AUTOSAR XML (schema 4-2-2)
package /AUTOLIV/SoftwareComponents/BswMIf
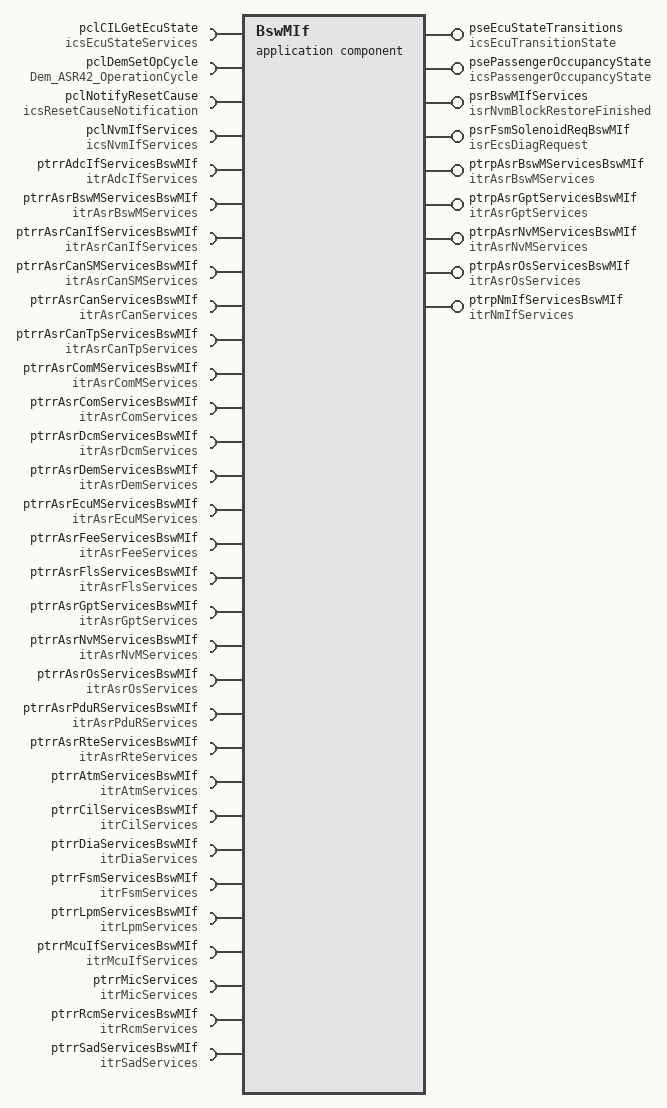
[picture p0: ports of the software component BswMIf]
  application sw component type BswMIf: category=BSW_System_Services
    4 x require port:
      pclCILGetEcuState: client-com-spec=updateCurrentEcuState, required-interface=icsEcuStateServices  # # Architecture Element ID ARCH_SW_BswMIf_pclCILGetEcuState_BswM_Cyclic_10msTimer # Description - The interface shall be used to update the ECU state in CIL module. # Data Flow ## Inputs: - {Current ECU State} # Linked Runnable - BswM_Cyclic_10msTimer #Traceability ---------------------------------------------------------------------------------------------------------------------- # Architecture Element ID ARCH_SW_BswMIf_pclCILGetEcuState_BswM_OnStartupTwoB # Description - The interface shall be used to update the ECU state in CIL module. # Data Flow ## Inputs: - {Current ECU State} # Linked Runnable - BswM_OnStartupTwoB #Traceability ---------------------------------------------------------------------------------------------------------------------- # Architecture Element ID ARCH_SW_BswMIf_pclCILGetEcuState_BswM_OnRunFromWakeup # Description - The interface shall be used to update the ECU state in CIL module. # Data Flow ## Inputs: - {Current ECU State} # Linked Runnable - BswM_OnRunFromWakeup #Traceability ---------------------------------------------------------------------------------------------------------------------- # Architecture Element ID ARCH_SW_BswMIf_pclCILGetEcuState_BswM_OnPostRunFromRun # Description - The interface shall be used to update the ECU state in CIL module. # Data Flow ## Inputs: - {Current ECU State} # Linked Runnable - BswM_OnPostRunFromRun #Traceability ---------------------------------------------------------------------------------------------------------------------- # Architecture Element ID ARCH_SW_BswMIf_pclCILGetEcuState_BswM_OnRunFromPostRunBusAvailable # Description - The interface shall be used to update the ECU state in CIL module. # Data Flow ## Inputs: - {Current ECU State} # Linked Runnable - BswM_OnRunFromPostRunBusAvailable #Traceability ---------------------------------------------------------------------------------------------------------------------- # Architecture Element ID ARCH_SW_BswMIf_pclCILGetEcuState_BswM_OnRunFromPostRunPassengerDetected # Description - The interface shall be used to update the ECU state in CIL module. # Data Flow ## Inputs: - {Current ECU State} # Linked Runnable - BswM_OnRunFromPostRunPassengerDetected #Traceability ---------------------------------------------------------------------------------------------------------------------- # Architecture Element ID ARCH_SW_BswMIf_pclCILGetEcuState_BswM_OnRunFromLowPwrPassengerDetected # Description - The interface shall be used to update the ECU state in CIL module. # Data Flow ## Inputs: - {Current ECU State} # Linked Runnable - BswM_OnRunFromLowPwrPassengerDetected #Traceability ---------------------------------------------------------------------------------------------------------------------- # Architecture Element ID ARCH_SW_BswMIf_pclCILGetEcuState_BswM_OnRunFromLowPwrBusAvailable # Description - The interface shall be used to update the ECU state in CIL module. # Data Flow ## Inputs: - {Current ECU State} # Linked Runnable - BswM_OnRunFromLowPwrBusAvailable #Traceability ----------------------------------------------------------------------------------------------------------------------
      pclDemSetOpCycle: client-com-spec=SetOperationCycleState, required-interface=Dem_ASR42_OperationCycle  # # Architecture Element ID ARCH_SW_BswMIf_pclDemSetOpCycle_BswM_OnStartComEffective # Description - The interface shall be used to set operation cycle of Dem module. # Data Flow ## Inputs: - {Cycle state} # Linked Runnable - BswM_OnStartComEffective #Traceability
      pclNotifyResetCause: client-com-spec=NotifyResetCause, required-interface=icsResetCauseNotification  # # Architecture Element ID ARCH_SW_BswMIf_pclNotifyResetCause_BswM_HWResetNotification # Description - The interface shall be used to set notify the reset casuse in RCM module. # Data Flow ## Inputs: - {Reset Cause Notification Type} - {Reset Cause Status} # Linked Runnable - BswM_HWResetNotification #Traceability --------------------------------------------------------------------------------------------------------------------- # Architecture Element ID ARCH_SW_BswMIf_pclNotifyResetCause_BswM_BswM_SWResetNotification # Description - The interface shall be used to set notify the reset casuse in RCM module. # Data Flow ## Inputs: - {Reset Cause Notification Type} - {Reset Cause Status} # Linked Runnable - BswM_SWResetNotification #Traceability --------------------------------------------------------------------------------------------------------------------- # Architecture Element ID ARCH_SW_BswMIf_pclNotifyResetCause_BswM_JumpToFBLNotification # Description - The interface shall be used to set notify the reset casuse in RCM module. # Data Flow ## Inputs: - {Reset Cause Notification Type} - {Reset Cause Status} # Linked Runnable - BswM_JumpToFBLNotification #Traceability
      pclNvmIfServices: required-interface=icsNvmIfServices  # # Architecture Element ID ARCH_SW_BswMIf_pclNvmIfServices_GetNvmBlockStatus # Description - The interface shall be used to get the current status of a NvM Block # Data Flow ## Inputs: - {Block Id} ## Outputs: - {Block Status} # Linked Runnable - BswMIf_runMainFunction #Traceability ------------------------------------------------------------------------------------------------------------------------------------------------ # Architecture Element ID ARCH_SW_BswMIf_pclNvmIfServices_RestoreRAMBlockDefaults # Description - The interface shall be used to restore to default a RAM Block. # Data Flow ## Inputs: - {Block Id} ## Outputs: - None # Linked Runnable - BswMIf_runMainFunction #Traceability ------------------------------------------------------------------------------------------------------------------------------------------------ # Architecture Element ID ARCH_SW_BswMIf_pclNvmIfServices_SetRamBlockStatus # Description - The interface shall be used to set to set the status of a RAM Block. # Data Flow ## Inputs: - {Block Id} - {Block Status} ## Outputs: - None # Linked Runnable - BswMIf_runMainFunction #Traceability ------------------------------------------------------------------------------------------------------------------------------------------------
        required-com-specs:
          GetNvmBlockLength
          GetNvmBlockStatus
          ReadBlockByAddress
          RestorePRAMBlockDefaults
          SetRamBlockStatus
          WriteBlockByAddress
          WriteNvmBlock
    9 x provide port:
      pseEcuStateTransitions: server-com-spec{operation=BswM_SetEcuStateTransitionStatus, queue-length=1}, provided-interface=icsEcuTransitionState  # # Architecture Element ID ARCH_SW_BswMIf_pseECUStateTransitions # Description - The BswM_SetEcuStateTransitionStatus shall be called in order to set the current status of RunToLowPowerTransition. - This status is necessary because sometimes the BswM Rule is validated before RX Acknowledge and POST RUN state is reached. # Data Flow ## Inputs: - {State of transition} - Can be one of the following values: FALSE, TRUE ## Outputs: - None # Linked Runnable - BswM_SetEcuStateTransitionStatus # Traceability DOM_eCS_TF_P_317
      psePassengerOccupancyState: server-com-spec{operation=BswM_UpdatePassangerOccupancyStatus, queue-length=1}, provided-interface=icsPassengerOccupancyState  # # Architecture Element ID ARCH_SW_BswMIf_psePassengerOccupancyState # Description - The BswM_UpdatePassangerOccupancyStatus shall be called in order to set the status of PassangerOccupancy state. # Data Flow ## Inputs: - {State of passenger occupancy} - PASSENGER_DETECTED ## Outputs: - None # Linked Runnable - BswM_UpdatePassangerOccupancyStatus # Traceability DOM_eCS_TF_P_204, DOM_eCS_TF_P_362, DOM_eCS_TF_P_363
      psrBswMIfServices: nonqueued-sender-com-spec{data-element=u8BlockRestoreStatus, uses-end-to-end-protection=0, init-value=B_FALSE:85}, provided-interface=isrNvmBlockRestoreFinished  # # Architecture Element ID ARCH_SW_BswMIf_psrBswMIfServices # Description - The interface shall be used to write the NvM block restore status from the BswMIf module # Data Flow ## Inputs ## Outputs - {Block Restore Status} - Can be one of the following values: FALSE, TRUE #Linked Runnable - BswMIf_runMainFunction # Traceability
      psrFsmSolenoidReqBswMIf: provided-interface=isrEcsDiagRequest  # # Architecture Element ID ARCH_SW_BswMIf_psrFsmSolenoidReqBswMIf_BswM_OnRunFromSafeState # Description - The runnable shall write the interface in order to trigger an unlock/lock for a certain solenoid # Data Flow ## Inputs: - {On demand self-test} ## Outputs - {Solenoid Command} - Can be UNLOCK/LOCK/NO_REQUEST - {Solenoid Command Complement} - Can be ~UNLOCK/~LOCK/~NO_REQUEST # Linked Runnable - BswM_OnRunFromSafeState # Traceability ----------------------------------------------------------------------------------------------------------------------------- # Architecture Element ID ARCH_SW_BswMIf_psrFsmSolenoidReqBswMIf_BswM_OnSafeStateFromPostRun # Description - The runnable shall write the interface in order to trigger an unlock/lock for a certain solenoid # Data Flow ## Inputs: - {On demand self-test} ## Outputs - {Solenoid Command} - Can be UNLOCK/LOCK/NO_REQUEST - {Solenoid Command Complement} - Can be ~UNLOCK/~LOCK/~NO_REQUEST # Linked Runnable - BswM_OnSafeStateFromPostRun # Traceability DOM_eCS_TF_P_351
        provided-com-specs:
          data-element=au8DiagReq, uses-end-to-end-protection=0, init-value=6 x KU8_NO_DIAG_REQUEST
          data-element=au8DiagReqComplement, uses-end-to-end-protection=0, init-value=6 x KU8_NO_DIAG_REQUEST
      ptrpAsrBswMServicesBswMIf: provided-interface=itrAsrBswMServices  # # Architecture Element ID ARCH_SW_BswMIf_ptrpAsrBswMServicesBswMIf_BswM_OnRunFromSafeState # Description - The BswM_OnRunFromSafeState runnable shall be called by the Autosar BswM in case of: - Transition from WAKEUP to RUN - Transition from LOW POWER to RUN (can wakeup detected) - Transiton from LOW POWER to RUN (passenger detected) # Data Flow #Linked Runnable - BswM_OnRunFromSafeState # Traceability -------------------------------------------------------------------------------------------------------------------------------- # Architecture Element ID ARCH_SW_BswMIf_ptrpAsrBswMServicesBswMIf_BswM_OnSafeStateFromPostRun # Description - The BswM_OnSafeStateFromPostRun runnable shall be called by the Autosar BswM in case of: - Transition from POST RUN to LOW POWER # Data Flow #Linked Runnable - BswM_OnSafeStateFromPostRun # Traceability -------------------------------------------------------------------------------------------------------------------------------- # Architecture Element ID ARCH_SW_BswMIf_ptrpAsrBswMServicesBswMIf_BswM_OnWakeupExpired # Description - The BswM_OnWakeupExpired runnable shall be called by the Autosar BswM in case of: - wakeup validation expired and wakeup status expired after 5000ms # Data Flow #Linked Runnable - BswM_OnWakeupExpired # Traceability DOM_eCS_TF_P_337, DOM_eCS_TF_P_371 -------------------------------------------------------------------------------------------------------------------------------- # Architecture Element ID ARCH_SW_BswMIf_ptrpAsrBswMServicesBswMIf_BswM_HWResetNotification # Description - The BswM_HWResetNotification runnable shall be called by the Autosar BswM in case of: - HW Reset Request # Data Flow #Linked Runnable - BswM_HWResetNotification # Traceability -------------------------------------------------------------------------------------------------------------------------------- # Architecture Element ID ARCH_SW_BswMIf_ptrpAsrBswMServicesBswMIf_BswM_JumpToFBLNotification # Description - The BswM_JumpToFBLNotification runnable shall be called by the Autosar BswM in case of: - Jump to Bootloader Reset Request # Data Flow #Linked Runnable - BswM_JumpToFBLNotification # Traceability DOM_eCS_TF_P_170 -------------------------------------------------------------------------------------------------------------------------------- # Architecture Element ID ARCH_SW_BswMIf_ptrpAsrBswMServicesBswMIf_BswM_SWResetNotification # Description - The BswM_SWResetNotification runnable shall be called by the Autosar BswM in case of: - SW Reset Request # Data Flow #Linked Runnable - BswM_SWResetNotification # Traceability DOM_eCS_TF_P_169 -------------------------------------------------------------------------------------------------------------------------------- # Architecture Element ID ARCH_SW_BswMIf_ptrpAsrBswMServicesBswMIf_BswM_On_Prep_Shutdown # Description - The BswM_On_Prep_Shutdown runnable shall be called by the Autosar BswM in case of: - Post Run timer exceed his maximum value AND buckle and SBS sensors are not available - Low Power timer exceed his maximum value AND no valid passenger occupancy or bus activity is detected # Data Flow #Linked Runnable - BswM_On_Prep_Shutdown # Traceability DOM_eCS_TF_P_284, DOM_eCS_TF_P_285, DOM_eCS_TF_P_216, DOM_eCS_TF_P_373, DOM_eCS_TF_P_374 -------------------------------------------------------------------------------------------------------------------------------- # Architecture Element ID ARCH_SW_BswMIf_ptrpAsrBswMServicesBswMIf_BswM_OnDisableTxPdu # Description - The BswM_OnDisableTxPdu runnable shall be called by the Autosar BswM in case of: - Current state of ECU is RUN AND Bus communication timeout is received # Data Flow #Linked Runnable - BswM_OnDisableTxPdu # Traceability DOM_eCS_TF_P_195, DOM_eCS_TF_P_222 -------------------------------------------------------------------------------------------------------------------------------- # Architecture Element ID ARCH_SW_BswMIf_ptrpAsrBswMServicesBswMIf_BswM_OnEnableTxPdu # Description - The BswM_OnEnableTxPdu runnable shall be called by the Autosar BswM in case of: - Bus communication is available {reception aknowledge is received} # Data Flow #Linked Runnable - BswM_OnEnableTxPdu # Traceability DOM_eCS_TF_P_341, DOM_eCS_TF_P_342, DOM_eCS_TF_P_364, DOM_eCS_TF_P_345, DOM_eCS_TF_P_346, DOM_eCS_TF_P_360, DOM_eCS_TF_P_361, DOM_eCS_TF_P_365, DOM_eCS_TF_P_355, DOM_eCS_TF_P_356, DOM_eCS_TF_P_347 -------------------------------------------------------------------------------------------------------------------------------- # Architecture Element ID ARCH_SW_BswMIf_ptrpAsrBswMServicesBswMIf_BswM_OnGoOffOneA # Description - The BswM_OnGoOffOneA runnable shall be called by the Autosar BswM in case of: - First part of the shutdown procedure {BswM_On_Prep_Shutdown} is made # Data Flow #Linked Runnable - BswM_OnGoOffOneA # Traceability DOM_eCS_TF_P_272 -------------------------------------------------------------------------------------------------------------------------------- # Architecture Element ID ARCH_SW_BswMIf_ptrpAsrBswMServicesBswMIf_BswM_OnLowPwrFromPostRun # Description - The BswM_OnLowPwrFromPostRun runnable shall be called by the Autosar BswM in case of: - Low Power state is requested {current state of ECU is POST RUN State} # Data Flow #Linked Runnable - BswM_OnLowPwrFromPostRun # Traceability DOM_eCS_TF_P_200 -------------------------------------------------------------------------------------------------------------------------------- # Architecture Element ID ARCH_SW_BswMIf_ptrpAsrBswMServicesBswMIf_BswM_OnPostRunFromRun # Description - The BswM_OnPostRunFromRun runnable shall be called by the Autosar BswM in case of: - The current state of ECU is RUN AND Bus communication timeout is received # Data Flow #Linked Runnable - BswM_OnPostRunFromRun # Traceability DOM_eCS_TF_P_168, DOM_eCS_TF_P_190, DOM_eCS_TF_P_263, DOM_eCS_TF_P_350 -------------------------------------------------------------------------------------------------------------------------------- # Architecture Element ID ARCH_SW_BswMIf_ptrpAsrBswMServicesBswMIf_BswM_OnRunFromLowPwrBusAvailable # Description - The BswM_OnRunFromLowPwrBusAvailable runnable shall be called by the Autosar BswM in case of: - The current state of ECU is LOW POWER AND a Passive wakeup is detected {CAN Bus activity} # Data Flow #Linked Runnable - BswM_OnRunFromLowPwrBusAvailable # Traceability DOM_eCS_TF_P_214 -------------------------------------------------------------------------------------------------------------------------------- # Architecture Element ID ARCH_SW_BswMIf_ptrpAsrBswMServicesBswMIf_BswM_OnRunFromLowPwrPassengerDetected # Description - The BswM_OnRunFromLowPwrPassengerDetected runnable shall be called by the Autosar BswM in case of: - The current state of ECU is LOW POWER AND an Active wakeup is detected {passenger occupancy detected} # Data Flow #Linked Runnable - BswM_OnRunFromLowPwrPassengerDetected # Traceability DOM_eCS_TF_P_317, DOM_eCS_TF_P_323 -------------------------------------------------------------------------------------------------------------------------------- # Architecture Element ID ARCH_SW_BswMIf_ptrpAsrBswMServicesBswMIf_BswM_OnRunFromPostRunBusAvailable # Description - The BswM_OnRunFromPostRunBusAvailable runnable shall be called by the Autosar BswM in case of: - The current state of ECU is POST RUN AND Bus communication is available {reception aknowledge is received} # Data Flow #Linked Runnable - BswM_OnRunFromPostRunBusAvailable # Traceability DOM_eCS_TF_P_193, DOM_eCS_TF_P_202 -------------------------------------------------------------------------------------------------------------------------------- # Architecture Element ID ARCH_SW_BswMIf_ptrpAsrBswMServicesBswMIf_BswM_OnRunFromPostRunPassengerDetected # Description - The BswM_OnRunFromPostRunPassengerDetected runnable shall be called by the Autosar BswM in case of: - The current state of ECU is POST RUN AND Valid Passenger occupancy is detected # Data Flow #Linked Runnable - BswM_OnRunFromPostRunPassengerDetected # Traceability DOM_eCS_TF_P_313, DOM_eCS_TF_P_323 -------------------------------------------------------------------------------------------------------------------------------- # Architecture Element ID ARCH_SW_BswMIf_ptrpAsrBswMServicesBswMIf_BswM_OnRunFromWakeup # Description - The BswM_OnRunFromWakeup runnable shall be called by the Autosar BswM in case of: - Wakeup is validated and all modules were initialized {BswM_OnStartComEffective} # Data Flow #Linked Runnable - BswM_OnRunFromWakeup # Traceability DOM_eCS_TF_P_235, DOM_eCS_TF_P_158, DOM_eCS_TF_P_343, DOM_eCS_TF_P_359, DOM_eCS_TF_P_344, DOM_eCS_TF_P_348, DOM_eCS_TF_P_335, DOM_eCS_TF_P_140 -------------------------------------------------------------------------------------------------------------------------------- # Architecture Element ID ARCH_SW_BswMIf_ptrpAsrBswMServicesBswMIf_BswM_OnStartComEffective # Description - The BswM_OnStartComEffective runnable shall be called by the Autosar BswM in case of: - Bus communication is available AND wakeup was validated # Data Flow #Linked Runnable - BswM_OnStartComEffective # Traceability DOM_eCS_TF_P_339, DOM_eCS_TF_P_344, DOM_eCS_TF_P_348 -------------------------------------------------------------------------------------------------------------------------------- # Architecture Element ID ARCH_SW_BswMIf_ptrpAsrBswMServices_BswMIf_BswM_OnStartupTwoA # Description - The BswM_OnStartupTwoA runnable shall be called by the Autosar BswM in case of: - First part of ECU initialization is done {EcuM_StartupOne, EcuM_StartupTwo} # Data Flow #Linked Runnable - BswM_OnStartupTwoA # Traceability DOM_eCS_TF_P_138, DOM_eCS_TF_P_280, DOM_eCS_TF_P_333, DOM_eCS_TF_P_334 -------------------------------------------------------------------------------------------------------------------------------- # Architecture Element ID ARCH_SW_BswMIf_ptrpAsrBswMServicesBswMIf_BswM_OnStartupTwoB # Description - The BswM_OnStartupTwoB runnable shall be called by the Autosar BswM in case of: - ReadAll NvM procedure is made {After second part of ECU initialization - BswM_OnStartupTwoB} # Data Flow #Linked Runnable - BswM_OnStartupTwoB # Traceability DOM_eCS_TF_P_333, DOM_eCS_TF_P_334 -------------------------------------------------------------------------------------------------------------------------------- # Architecture Element ID ARCH_SW_BswMIf_ptrpAsrBswMServicesBswMIf_BswM_OnWakeupValidation # Description - The BswM_OnWakeupValidation runnable shall be called by the Autosar BswM in case of: - Wakeup event is validated # Data Flow #Linked Runnable - BswM_OnWakeupValidation # Traceability DOM_eCS_TF_P_73, DOM_eCS_TF_P_339 -------------------------------------------------------------------------------------------------------------------------------- # Architecture Element ID ARCH_SW_BswMIf_ptrpAsrBswMServicesBswMIf_BswM_ProceedReset # Description - The BswM_ProceedReset runnable shall be called by the Autosar BswM in case of: - SW Reset diagnosis request is made - HW Reset diagnosis request is made - FBL Reset diagnosis request is made # Data Flow #Linked Runnable - BswM_ProceedReset # Traceability DOM_eCS_TF_P_169, DOM_eCS_TF_P_170, DOM_eCS_TF_P_373, DOM_eCS_TF_P_374
      ptrpAsrGptServicesBswMIf: provided-interface=itrAsrGptServices  # # Architecture Element ID ARCH_SW_BswMIf_ptrpAsrGptServicesBswMIf_BswM_Cyclic_10msTimer # Description - The BswM_Cyclic_10msTimer runnable shall be called when the Gpt timer expires via the Gpt_InitChannelPB_TDK_4G runnable # Data Flow # Linked Runnable - BswM_Cyclic_10msTimer # Traceability DOM_eCS_TF_P_277, DOM_eCS_TF_P_278, DOM_eCS_TF_P_279, DOM_eCS_TF_P_192, DOM_eCS_TF_P_257, DOM_eCS_TF_P_285, DOM_eCS_TF_P_284, DOM_eCS_TF_P_202, DOM_eCS_TF_P_313, DOM_eCS_TF_P_263, DOM_eCS_TF_P_200, DOM_eCS_TF_P_235, DOM_eCS_TF_P_323, DOM_eCS_TF_P_349, DOM_eCS_TF_P_159, DOM_eCS_TF_P_350
      ptrpAsrNvMServicesBswMIf: provided-interface=itrAsrNvMServices  # # Architecture Element ID ARCH_SW_BswMIf_ptrpAsrNvMServicesBswMIf_BswM_CB_NfyNvMJobEnd # Description - The BswM_CB_NfyNvMJobEnd runnable shall be called when the NvM Read or Write job is finished. # Data Flow # Linked Runnable - BswM_CB_NfyNvMJobEnd # Traceability DOM_eCS_TF_P_273
      ptrpAsrOsServicesBswMIf: provided-interface=itrAsrOsServices  # # Architecture Element ID ARCH_SW_BswMIf_ptrpAsrOsServicesBswMIf_BswMIf_runMainFunction # Description - The BswMIf_runMainFunction runnable shall be called when the Os task {OsTask_Alv_Autotests} is executed # Data Flow # Linked Runnable - BswMIf_runMainFunction # Traceability DOM_eCS_TF_P_339, DOM_eCS_TF_P_155, DOM_eCS_TF_P_189, DOM_eCS_TF_P_353, DOM_eCS_TF_P_354, DOM_eCS_TF_P_357, DOM_eCS_TF_P_358 -------------------------------------------------------------------------------------------------------------------------------- # Architecture Element ID ARCH_SW_BswMIf_OsTask_Bsw_ReadWrite_AllProcess # Description - The OsTask_Bsw_ReadWrite_AllProcess runnable shall be called when the Os task {OsTask_Bsw_ReadWrite_AllProcess} is executed # Data Flow # Linked Runnable - OsTask_Bsw_ReadWrite_AllProcess # Traceability -------------------------------------------------------------------------------------------------------------------------------- # Architecture Element ID ARCH_SW_BswMIf_OsTask_AppIdle # Description - The OsTask_AppIdle runnable shall be called when the Os task {OsTask_AppIdle} is executed # Data Flow # Linked Runnable - OsTask_AppIdle # Traceability
      ptrpNmIfServicesBswMIf: provided-interface=itrNmIfServices  # # Architecture Element ID ARCH_SW_BswMIf_ptrpNmIfServicesBswMIf_BswM_SetEcuStateTransitionStatus # Description - The BswM_SetEcuStateTransitionStatus runnable shall be called when bus acknowledge is received and NmIf_runMainFunction runnable is executed. # Data Flow # Linked Runnable - BswM_SetEcuStateTransitionStatus # Traceability
    27 x require port:
      ptrrAdcIfServicesBswMIf: required-interface=itrAdcIfServices  # # Architecture Element ID ARCH_SW_BswMIf_ptrrAdcIfServicesBswMIf_AdcIf_runInit_BswM_OnStartupTwoA # Description - The AdcIf_runInit runnable shall be called in the BswM_OnStartupTwoA runnable in order to initialize the AdcIf module and to start the Adc conversions. # Data Flow # Linked Runnable - BswM_OnStartupTwoA #Traceability DOM_eCS_TF_P_311 --------------------------------------------------------------------------------------------------------------------------------------------- # Architecture Element ID ARCH_SW_BswMIf_ptrrAdcIfServicesBswMIf_AdcIf_runDeInit_BswM_OnGoOffOneA # Description - The AdcIf_runDeInit runnable shall be called in the BswM_OnGoOffOneA runnable in order to deinitialize the AdcIf module and to stop the Adc conversions. # Data Flow # Linked Runnable - BswM_OnGoOffOneA #Traceability DOM_eCS_TF_P_272
      ptrrAsrBswMServicesBswMIf: required-interface=itrAsrBswMServices  # # Architecture Element ID ARCH_SW_BswMIf_ptrrBswMServicesBswMIf_BswM_RequestMode_BswM_Cyclic_10msTimer # Description - The BswM_RequestMode runnable shall be called in the BswM_Cyclic_10msTimer runnable in order to: - Set BswM Passenger Occupancy port to notify that pasager occupancy was detected - Set BswM Passenger Occupancy port to notify that pasager occupancy was not detected - Set BswM ECU Shutdown Port to be able to notify that SHUTDOWN state is requested - Set BswM EcuState Port to be able to notify that LOW POWER state is requested - Set BswM EcuState Port to be able to notify that RUN state is requested - Set BswM TX PDU request port to notify that TX Pdu disable is requested # Data Flow # Linked Runnable - BswM_Cyclic_10msTimer #Traceability DOM_eCS_TF_P_192, DOM_eCS_TF_P_257, DOM_eCS_TF_P_285, DOM_eCS_TF_P_284, DOM_eCS_TF_P_313, DOM_eCS_TF_P_263 --------------------------------------------------------------------------------------------------------------------------------------- # Architecture Element ID ARCH_SW_BswMIf_ptrrBswMServicesBswMIf_BswM_RequestMode_BswM_OnStartupTwoA # Description - The BswM_RequestMode runnable shall be called in the BswM_OnStartupTwoA runnable in order to: - Request to start the process to fastened the ReadAll process # Data Flow # Linked Runnable - BswM_OnStartupTwoA #Traceability DOM_eCS_TF_P_295 --------------------------------------------------------------------------------------------------------------------------------------- # Architecture Element ID ARCH_SW_BswMIf_ptrrBswMServicesBswMIf_BswM_RequestMode_BswM_CB_NfyNvMJobEnd # Description - The BswM_RequestMode runnable shall be called in the BswM_CB_NfyNvMJobEnd runnable in order to: - Set BswM Request Port to be able to notify that initialization phase shall continue {init phase - StartupTwoB} - Set BswM Request Port to be able to reset the passenger occupancy status if writeAll procedure is triggered when transition from autonomous run to run is made - Set BswM Request Port to be able to set the ecu state to RUN if writeAll procedure is triggered when transition from autonomous run to run is made - Set BswM Request Port to be able to notify that de-initialization phase shall continue {de-init phase - GoOffOneA} # Data Flow # Linked Runnable - BswM_CB_NfyNvMJobEnd #Traceability --------------------------------------------------------------------------------------------------------------------------------------- # Architecture Element ID ARCH_SW_BswMIf_ptrrBswMServicesBswMIf_BswM_RequestMode_BswM_OnStartupTwoB # Description - The BswM_RequestMode runnable shall be called in the BswM_OnStartupTwoB runnable in order to: - Set BswM Request Port to be able to notify that initialization phase shall continue {wait for wake-up validation} # Data Flow # Linked Runnable - BswM_OnStartupTwoB #Traceability DOM_eCS_TF_P_296 --------------------------------------------------------------------------------------------------------------------------------------- # Architecture Element ID ARCH_SW_BswMIf_ptrrBswMServicesBswMIf_BswM_RequestMode_BswM_OnStartComEffective # Description - The BswM_RequestMode runnable shall be called in the BswM_OnStartComEffective runnable in order to: - Set BswM EcuState Port to be able to notify that Wakeup mode ready state is requested - Set BswM Request Port to be able to notify that wakeup was validated # Data Flow # Linked Runnable - BswM_OnStartComEffective #Traceability --------------------------------------------------------------------------------------------------------------------------------------- # Architecture Element ID ARCH_SW_BswMIf_ptrrBswMServicesBswMIf_BswM_RequestMode_BswM_OnRunFromWakeup # Description - The BswM_RequestMode runnable shall be called in the BswM_OnRunFromWakeup runnable in order to: - Set BswM EcuState Port to be able to notify that RUN state is requested # Data Flow # Linked Runnable - BswM_OnRunFromWakeup #Traceability --------------------------------------------------------------------------------------------------------------------------------------- # Architecture Element ID ARCH_SW_BswMIf_ptrrBswMServicesBswMIf_BswM_RequestMode_BswM_OnPostRunFromRun # Description - The BswM_RequestMode runnable shall be called in the BswM_OnPostRunFromRun runnable in order to: - Request to start the process to fastened the ReadAll process - Set BswM EcuState Port to be able to notify that POST RUN state is requested # Data Flow # Linked Runnable - BswM_OnPostRunFromRun #Traceability DOM_eCS_TF_P_264 --------------------------------------------------------------------------------------------------------------------------------------- # Architecture Element ID ARCH_SW_BswMIf_ptrrBswMServicesBswMIf_BswM_RequestMode_BswM_OnRunFromPostRunBusAvailable # Description - The BswM_RequestMode runnable shall be called in the BswM_OnRunFromPostRunBusAvailable runnable in order to: - Set BswM EcuState Port to be able to notify that RUN state is requested # Data Flow # Linked Runnable - BswM_OnRunFromPostRunBusAvailable #Traceability DOM_eCS_TF_P_193, DOM_eCS_TF_P_202 --------------------------------------------------------------------------------------------------------------------------------------- # Architecture Element ID ARCH_SW_BswMIf_ptrrBswMServicesBswMIf_BswM_RequestMode_BswM_OnRunFromPostRunPassengerDetected # Description - The BswM_RequestMode runnable shall be called in the BswM_OnRunFromPostRunPassengerDetected runnable in order to: - Set BswM EcuState Port to be able to notify that RUN NO COMM state is requested - Set BswM TX PDU request port to notify that wait TX Pdu is requested {used to not trigger other rules} # Data Flow # Linked Runnable - BswM_OnRunFromPostRunPassengerDetected #Traceability --------------------------------------------------------------------------------------------------------------------------------------- # Architecture Element ID ARCH_SW_BswMIf_ptrrBswMServicesBswMIf_BswM_RequestMode_BswM_OnLowPwrFromPostRun # Description - The BswM_RequestMode runnable shall be called in the BswM_OnLowPwrFromPostRun runnable in order to: - Set BswM EcuState Port to be able to notify that LOW POWER state is requested # Data Flow # Linked Runnable - BswM_OnLowPwrFromPostRun #Traceability DOM_eCS_TF_P_200 --------------------------------------------------------------------------------------------------------------------------------------- # Architecture Element ID ARCH_SW_BswMIf_ptrrBswMServicesBswMIf_BswM_RequestMode_BswM_OnRunFromLowPwrPassengerDetected # Description - The BswM_RequestMode runnable shall be called in the BswM_OnRunFromLowPwrPassengerDetected runnable in order to: - Set BswM EcuState Port to be able to notify that RUN state is requested # Data Flow # Linked Runnable - BswM_OnRunFromLowPwrPassengerDetected #Traceability --------------------------------------------------------------------------------------------------------------------------------------- # Architecture Element ID ARCH_SW_BswMIf_ptrrBswMServicesBswMIf_BswM_RequestMode_BswM_OnRunFromLowPwrBusAvailable # Description - The BswM_RequestMode runnable shall be called in the BswM_OnRunFromLowPwrBusAvailable runnable in order to: - Set BswM EcuState Port to be able to notify that RUN state is requested # Data Flow # Linked Runnable - BswM_OnRunFromLowPwrBusAvailable #Traceability DOM_eCS_TF_P_214 --------------------------------------------------------------------------------------------------------------------------------------- # Architecture Element ID ARCH_SW_BswMIf_ptrrBswMServicesBswMIf_BswM_RequestMode_BswM_On_Prep_Shutdown # Description - The BswM_RequestMode runnable shall be called in the BswM_On_Prep_Shutdown runnable in order to: - Request to start the process to fastened the WriteAll process - Set BswM Request Port to be able to notify that de-initialization of modules shall be performed # Data Flow # Linked Runnable - BswM_On_Prep_Shutdown #Traceability DOM_eCS_TF_P_272 --------------------------------------------------------------------------------------------------------------------------------------- # Architecture Element ID ARCH_SW_BswMIf_ptrrBswMServicesBswMIf_BswM_RequestMode_BswM_OnGoOffOneA # Description - The BswM_RequestMode runnable shall be called in the BswM_OnGoOffOneA runnable in order to: - Set BswM Request Port to be able to notify that the second step of de-initialization of modules shall be performed # Data Flow # Linked Runnable - BswM_OnGoOffOneA #Traceability DOM_eCS_TF_P_272 --------------------------------------------------------------------------------------------------------------------------------------- # Architecture Element ID ARCH_SW_BswMIf_ptrrBswMServicesBswMIf_BswM_RequestMode_BswMIf_runMainFunction # Description - The BswM_RequestMode runnable shall be called in the BswMIf_runMainFunction runnable in order to: - Set BswM Request Port to be able to notify that PROCESS MODE state is requested # Data Flow # Linked Runnable - BswMIf_runMainFunction #Traceability
      ptrrAsrCanIfServicesBswMIf: required-interface=itrAsrCanIfServices  # # Architecture Element ID ARCH_SW_BswMIf_ptrrCanIfServicesBswMIf_CanIf_Init_BswM_OnStartupTwoA # Description - The CanIf_Init runnable shall be called in the BswM_OnStartupTwoA runnable in order to initialize the CAN interface. # Data Flow # Linked Runnable - BswM_OnStartupTwoA #Traceability --------------------------------------------------------------------------------------------------------------------------------------- # Architecture Element ID ARCH_SW_BswMIf_ptrrCanIfServicesBswMIf_CanIf_CheckWakeup_BswM_CB_NfyNvMJobEnd # Description - The CanIf_CheckWakeup runnable shall be called in the BswM_CB_NfyNvMJobEnd runnable in order to check for wakeup events. # Data Flow # Linked Runnable - BswM_CB_NfyNvMJobEnd #Traceability DOM_eCS_TF_P_152
      ptrrAsrCanSMServicesBswMIf: required-interface=itrAsrCanSMServices  # # Architecture Element ID ARCH_SW_BswMIf_ptrrCanSMServicesBswMIf_CanSM_Init_BswM_OnStartupTwoA # Description - The CanSM_Init runnable shall be called in the BswM_OnStartupTwoA runnable in order to initialize the CanSM module. # Data Flow # Linked Runnable - BswM_OnStartupTwoA #Traceability
      ptrrAsrCanServicesBswMIf: required-interface=itrAsrCanServices  # # Architecture Element ID ARCH_SW_BswMIf_ptrrCanServicesBswMIf_Can_SetControllerMode_BswM_OnStartupTwoA # Description - The Can_SetControllerMode runnable shall be called in the BswM_OnStartupTwoA runnable in order to put the CAN controller in START State. # Data Flow # Linked Runnable - BswM_OnStartupTwoA #Traceability ------------------------------------------------------------------------------------------------------------------------------------------- # Architecture Element ID ARCH_SW_BswMIf_ptrrCanServicesBswMIf_Can_EnableControllerInterrupts_BswM_OnStartupTwoA # Description - The Can_EnableControllerInterrupts runnable shall be called in the BswM_OnStartupTwoA runnable in order to enable CAN interrupts. # Data Flow # Linked Runnable - BswM_OnStartupTwoA #Traceability
      ptrrAsrCanTpServicesBswMIf: required-interface=itrAsrCanTpServices  # # Architecture Element ID ARCH_SW_BswMIf_ptrrCanTpServicesBswMIf_CanTp_Init_BswM_OnStartupTwoA # Description - The CanTp_Init runnable shall be called in the BswM_OnStartupTwoA runnable in order to initialize the CanTp module. # Data Flow # Linked Runnable - BswM_OnStartupTwoA #Traceability
      ptrrAsrComMServicesBswMIf: required-interface=itrAsrComMServices  # # Architecture Element ID ARCH_SW_BswMIf_ptrrComMServicesBswMIf_ComM_Init_BswM_OnStartupTwoB # Description - The ComM_Init runnable shall be called in the BswM_OnStartupTwoB runnable in order to initialize the ComM module. # Data Flow # Linked Runnable - BswM_OnStartupTwoB #Traceability -------------------------------------------------------------------------------------------------------------------------------------------------------- # Architecture Element ID ARCH_SW_BswMIf_ptrrComMServicesBswMIf_ComM_CommunicationAllowed_BswM_OnWakeupValidation # Description - The ComM_CommunicationAllowed runnable shall be called in the BswM_OnWakeupValidation runnable in order to authorize the start of communication # Data Flow # Linked Runnable - BswM_OnWakeupValidation #Traceability DOM_eCS_TF_P_153, DOM_eCS_TF_P_301 -------------------------------------------------------------------------------------------------------------------------------------------------------- # Architecture Element ID ARCH_SW_BswMIf_ptrrComMServicesBswMIf_ComM_ASR40_RequestComMode_BswM_OnWakeupValidation # Description - The ComM_ASR40_RequestComMode runnable shall be called in the BswM_OnWakeupValidation runnable in order to enable message transmission and reception. # Data Flow # Linked Runnable - BswM_OnWakeupValidation #Traceability DOM_eCS_TF_P_153, DOM_eCS_TF_P_300, DOM_eCS_TF_P_163, DOM_eCS_TF_P_166 -------------------------------------------------------------------------------------------------------------------------------------------------------- # Architecture Element ID ARCH_SW_BswMIf_ptrrComMServicesBswMIf_ComM_ASR40_RequestComMode_BswM_OnPostRunFromRun # Description - The ComM_ASR40_RequestComMode runnable shall be called in the BswM_OnPostRunFromRun runnable in order to set ComM back to full communication to be able to detect a wake-up request after post run state was entered. # Data Flow # Linked Runnable - BswM_OnPostRunFromRun #Traceability DOM_eCS_TF_P_194 -------------------------------------------------------------------------------------------------------------------------------------------------------- # Architecture Element ID ARCH_SW_BswMIf_ptrrComMServicesBswMIf_ComM_DeInit_BswM_OnGoOffOneA # Description - The ComM_DeInit runnable shall be called in the BswM_OnGoOffOneA runnable in order to de-initialize the ComM module. # Data Flow # Linked Runnable - BswM_OnGoOffOneA #Traceability DOM_eCS_TF_P_272, DOM_eCS_TF_P_367
      ptrrAsrComServicesBswMIf: required-interface=itrAsrComServices  # # Architecture Element ID ARCH_SW_BswMIf_ptrrComServicesBswMIf_Com_Init_BswM_OnStartupTwoA # Description - The Com_Init runnable shall be called in the BswM_OnStartupTwoA runnable in order to initialize the Com module. # Data Flow # Linked Runnable - BswM_OnStartupTwoA #Traceability -------------------------------------------------------------------------------------------------------------------------------------------------------- # Architecture Element ID ARCH_SW_BswMIf_ptrrComServicesBswMIf_Com_ClearIpduGroupVector_BswM_OnDisableTxPdu # Description - The Com_ClearIpduGroupVector runnable shall be called in the BswM_OnDisableTxPdu runnable in order to initialize the PDU group vector to 0 # Data Flow # Linked Runnable - BswM_OnDisableTxPdu #Traceability -------------------------------------------------------------------------------------------------------------------------------------------------------- # Architecture Element ID ARCH_SW_BswMIf_ptrrComServicesBswMIf_Com_SetIpduGroup_BswM_OnDisableTxPdu # Description - The Com_SetIpduGroup runnable shall be called in the BswM_OnDisableTxPdu runnable in order to set new states to RX and Tx Com IPDUs: - Enable frame reception - Disable frame transmission # Data Flow # Linked Runnable - BswM_OnDisableTxPdu #Traceability -------------------------------------------------------------------------------------------------------------------------------------------------------- # Architecture Element ID ARCH_SW_BswMIf_ptrrComServicesBswMIf_Com_IpduGroupControl_BswM_OnDisableTxPdu # Description - The Com_IpduGroupControl runnable shall be called in the BswM_OnDisableTxPdu runnable in order to start both COM PDUs (after their states have been updated) # Data Flow # Linked Runnable - BswM_OnDisableTxPdu #Traceability -------------------------------------------------------------------------------------------------------------------------------------------------------- # Architecture Element ID ARCH_SW_BswMIf_ptrrComServicesBswMIf_Com_ClearIpduGroupVector_BswM_OnEnableTxPdu # Description - The Com_ClearIpduGroupVector runnable shall be called in the BswM_OnEnableTxPdu runnable in order to initialize the PDU group vector to 0 # Data Flow # Linked Runnable - BswM_OnEnableTxPdu #Traceability DOM_eCS_TF_P_166 -------------------------------------------------------------------------------------------------------------------------------------------------------- # Architecture Element ID ARCH_SW_BswMIf_ptrrComServicesBswMIf_Com_SetIpduGroup_BswM_OnEnableTxPdu # Description - The Com_SetIpduGroup runnable shall be called in the BswM_OnEnableTxPdu runnable in order to set new states to RX and Tx Com IPDUs: - Enable frame reception - Enable frame transmission # Data Flow # Linked Runnable - BswM_OnEnableTxPdu #Traceability DOM_eCS_TF_P_166 -------------------------------------------------------------------------------------------------------------------------------------------------------- # Architecture Element ID ARCH_SW_BswMIf_ptrrComServicesBswMIf_Com_IpduGroupControl_BswM_OnEnableTxPdu # Description - The Com_IpduGroupControl runnable shall be called in the BswM_OnEnableTxPdu runnable in order to start both COM PDUs (after their states have been updated) # Data Flow # Linked Runnable - BswM_OnEnableTxPdu #Traceability DOM_eCS_TF_P_166
      ptrrAsrDcmServicesBswMIf: required-interface=itrAsrDcmServices  # # Architecture Element ID ARCH_SW_BswMIf_ptrrDcmServicesBswMIf_Dcm_Init_BswM_OnStartComEffective # Description - The Dcm_Init runnable shall be called in the BswM_OnStartComEffective runnable in order to initialize DCM module # Data Flow # Linked Runnable - BswM_OnStartComEffective #Traceability
      ptrrAsrDemServicesBswMIf: required-interface=itrAsrDemServices  # # Architecture Element ID ARCH_SW_BswMIf_ptrrDemServicesBswMIf_Dem_Init_BswM_OnStartupTwoB # Description - The Dem_Init runnable shall be called in the BswM_OnStartupTwoB runnable in order to initialize DEM module # Data Flow # Linked Runnable - BswM_OnStartupTwoB #Traceability -------------------------------------------------------------------------------------------------------------------------------------------------- # Architecture Element ID ARCH_SW_BswMIf_ptrrDemServicesBswMIf_Dem_Shutdown_BswM_On_Prep_Shutdown # Description - The Dem_Shutdown runnable shall be called in the BswM_On_Prep_Shutdown runnable in order to shutdown the DEM module # Data Flow # Linked Runnable - BswM_On_Prep_Shutdown #Traceability DOM_eCS_TF_P_272
      ptrrAsrEcuMServicesBswMIf: required-interface=itrAsrEcuMServices  # # Architecture Element ID ARCH_SW_BswMIf_ptrrEcuMServicesBswMIf_EcuM_ValidateWakeupEvent_BswM_OnStartupTwoB # Description - The EcuM_ValidateWakeupEvent runnable shall be called in the BswM_OnStartupTwoB runnable in order to validate wakeup event # Data Flow # Linked Runnable - BswM_OnStartupTwoB #Traceability DOM_eCS_TF_P_296, DOM_eCS_TF_P_273, DOM_eCS_TF_P_237 --------------------------------------------------------------------------------------------------------------------------------------------- # Architecture Element ID ARCH_SW_BswMIf_ptrrEcuMServicesBswMIf_EcuM_ClearWakeupEvent_BswM_OnStartComEffective # Description - The EcuM_ClearWakeupEvent runnable shall be called in the BswM_OnStartComEffective runnable in order to acknowledge wake validation information # Data Flow # Linked Runnable - BswM_OnStartComEffective #Traceability DOM_eCS_TF_P_303 --------------------------------------------------------------------------------------------------------------------------------------------- # Architecture Element ID ARCH_SW_BswMIf_ptrrEcuMServicesBswMIf_EcuM_ClearWakeupEvent_BswM_On_Prep_Shutdown # Description - The EcuM_ClearWakeupEvent runnable shall be called in the BswM_On_Prep_Shutdown runnable in order to acknowledge wake validation information # Data Flow # Linked Runnable - BswM_On_Prep_Shutdown #Traceability --------------------------------------------------------------------------------------------------------------------------------------------- # Architecture Element ID ARCH_SW_BswMIf_ptrrEcuMServicesBswMIf_EcuM_GoDown_BswM_ProceedReset # Description - The EcuM_GoDown runnable shall be called in the BswM_ProceedReset runnable in order to prepare for a power off/reset # Data Flow # Linked Runnable - BswM_ProceedReset #Traceability DOM_eCS_TF_P_218 --------------------------------------------------------------------------------------------------------------------------------------------- # Architecture Element ID ARCH_SW_BswMIf_ptrrEcuMServicesBswMIf_EcuM_GoDown_BswM_OnWakeupExpired # Description - The EcuM_GoDown runnable shall be called in the BswM_OnWakeupExpired runnable in order to prepare for a power off/reset # Data Flow # Linked Runnable - BswM_OnWakeupExpired #Traceability
      ptrrAsrFeeServicesBswMIf: required-interface=itrAsrFeeServices  # # Architecture Element ID ARCH_SW_BswMIf_ptrrFeeServicesBswMIf_Fee_MainFunction_OsTask_Bsw_ReadWrite_AllProcess # Description - The Fee_MainFunction runnable shall be called in the OsTask_Bsw_ReadWrite_AllProcess runnable in order to read/write or erase fee jobs # Data Flow # Linked Runnable - OsTask_Bsw_ReadWrite_AllProcess #Traceability DOM_eCS_TF_P_295, DOM_eCS_TF_P_273
      ptrrAsrFlsServicesBswMIf: required-interface=itrAsrFlsServices  # # Architecture Element ID ARCH_SW_BswMIf_ptrrFlsServicesBswMIf_Fls_MainFunction_OsTask_Bsw_ReadWrite_AllProcess # Description - The Fls_MainFunction runnable shall be called in the OsTask_Bsw_ReadWrite_AllProcess runnable in order to perform flash read/write/erase or compare fls jobs # Data Flow # Linked Runnable - OsTask_Bsw_ReadWrite_AllProcess #Traceability DOM_eCS_TF_P_295, DOM_eCS_TF_P_273
      ptrrAsrGptServicesBswMIf: required-interface=itrAsrGptServices  # # Architecture Element ID ARCH_SW_BswMIf_ptrrGptServicesBswMIf_Gpt_StopTimer_BswM_Cyclic_10msTimer # Description - The Gpt_StopTimer runnable shall be called in the BswM_Cyclic_10msTimer runnable in order to stop function of timer if: - Current ECU State is POST RUN AND Pasager occupancy is detected - Current ECU State is POST RUN AND Passenger occupancy OR CAN Activity is not detected - Current ECU State is AUTONOMOUS RUN {Passenger detected - valid transition from POST RUN} AND CAN Activity was detected on bus - Current ECU State is AUTONOMOUS RUN {Passenger detected - valid transition from POST RUN} AND CAN Activity was not detected on bus - Current ECU State is AUTONOMOUS RUN {Passenger detected - valid transition from LOW POWER} AND CAN Activity was detected on bus - Current ECU State is AUTONOMOUS RUN {Passenger detected - valid transition from LOW POWER} AND CAN Activity was not detected on bus # Data Flow # Linked Runnable - BswM_Cyclic_10msTimer #Traceability DOM_eCS_TF_P_284, DOM_eCS_TF_P_285, DOM_eCS_TF_P_313, DOM_eCS_TF_P_263 ---------------------------------------------------------------------------------------------------------------------------------------------------------------------------- # Architecture Element ID ARCH_SW_BswMIf_ptrrGptServicesBswMIf_Gpt_StartTimer_BswM_CB_NfyNvMJobEnd # Description - The Gpt_StartTimer runnable shall be called in the BswM_CB_NfyNvMJobEnd runnable in order to start GPT timer if: - WriteAll request was made by a valid transition from RUN in POST RUN # Data Flow # Linked Runnable - BswM_CB_NfyNvMJobEnd #Traceability DOM_eCS_TF_P_264 ---------------------------------------------------------------------------------------------------------------------------------------------------------------------------- # Architecture Element ID ARCH_SW_BswMIf_ptrrGptServicesBswMIf_Gpt_EnableNotification_BswM_OnStartupTwoB # Description - The Gpt_EnableNotification runnable shall be called in the BswM_OnStartupTwoB runnable in order to enable notification function on GPT timer. # Data Flow # Linked Runnable - BswM_OnStartupTwoB #Traceability ---------------------------------------------------------------------------------------------------------------------------------------------------------------------------- # Architecture Element ID ARCH_SW_BswMIf_ptrrGptServicesBswMIf_Gpt_StopTimer_BswM_OnRunFromPostRunBusAvailable # Description - The Gpt_StopTimer runnable shall be called in the BswM_OnRunFromPostRunBusAvailable runnable in order to stop GPT timer on LPIT2 if: - Ecu enters in RUN State {from POST RUN} # Data Flow # Linked Runnable - BswM_OnRunFromPostRunBusAvailable #Traceability DOM_eCS_TF_P_315, DOM_eCS_TF_P_202 ---------------------------------------------------------------------------------------------------------------------------------------------------------------------------- # Architecture Element ID ARCH_SW_BswMIf_ptrrGptServicesBswMIf_Gpt_StartTimer_BswM_OnRunFromPostRunPassengerDetected # Description - The Gpt_StartTimer runnable shall be called in the BswM_OnPostRunFromRun runnable in order to start GPT timer on LPIT2 if: - Ecu enters in RUN State {from POST RUN} # Data Flow # Linked Runnable - BswM_OnRunFromPostRunPassengerDetected #Traceability ---------------------------------------------------------------------------------------------------------------------------------------------------------------------------- # Architecture Element ID ARCH_SW_BswMIf_ptrrGptServicesBswMIf_Gpt_StartTimer_BswM_OnRunFromLowPwrPassengerDetected # Description - The Gpt_StartTimer runnable shall be called in the BswM_OnRunFromLowPwrPassengerDetected runnable in order to start GPT timer on LPIT2 if: - Ecu enters in RUN State {from LOW POWER} # Data Flow # Linked Runnable - BswM_OnRunFromLowPwrPassengerDetected #Traceability
      ptrrAsrNvMServicesBswMIf: required-interface=itrAsrNvMServices  # # Architecture Element ID ARCH_SW_BswMIf_ptrrNvMServicesBswMIf_NvM_Init_BswM_OnStartupTwoA # Description - The NvM_Init runnable shall be called in the BswM_OnStartupTwoA runnable in order to initialize NvM stack. # Data Flow # Linked Runnable - BswM_OnStartupTwoA #Traceability --------------------------------------------------------------------------------------------------------------------------------- # Architecture Element ID ARCH_SW_BswMIf_ptrrNvMServicesBswMIf_NvM_ReadAll_BswM_OnStartupTwoA # Description - The NvM_ReadAll runnable shall be called in the BswM_OnStartupTwoA runnable in order to start Read All process. # Data Flow # Linked Runnable - BswM_OnStartupTwoA #Traceability DOM_eCS_TF_P_295 --------------------------------------------------------------------------------------------------------------------------------- # Architecture Element ID ARCH_SW_BswMIf_ptrrNvMServicesBswMIf_NvM_WriteAll_BswM_OnPostRunFromRun # Description - The NvM_WriteAll runnable shall be called in the BswM_OnPostRunFromRun runnable in order to start Write All process. # Data Flow # Linked Runnable - BswM_OnPostRunFromRun #Traceability DOM_eCS_TF_P_264 --------------------------------------------------------------------------------------------------------------------------------- # Architecture Element ID ARCH_SW_BswMIf_ptrrNvMServicesBswMIf_NvM_WriteAll_BswM_Cyclic_10msTimer # Description - The NvM_WriteAll runnable shall be called in the BswM_Cyclic_10msTimer runnable in order to start Write All process. # Data Flow # Linked Runnable - BswM_OnPostRunFromRun #Traceability DOM_eCS_TF_P_264 --------------------------------------------------------------------------------------------------------------------------------- # Architecture Element ID ARCH_SW_BswMIf_ptrrNvMServicesBswMIf_NvM_WriteAll_BswM_On_Prep_Shutdown # Description - The NvM_WriteAll runnable shall be called in the BswM_On_Prep_Shutdown runnable in order to start Write All process. # Data Flow # Linked Runnable - BswM_On_Prep_Shutdown #Traceability DOM_eCS_TF_P_273 --------------------------------------------------------------------------------------------------------------------------------- # Architecture Element ID ARCH_SW_BswMIf_ptrrNvMServicesBswMIf_NvM_MainFunction_OsTask_Bsw_ReadWrite_AllProcess # Description - The NvM_MainFunction runnable shall be called in the OsTask_Bsw_ReadWrite_AllProcess runnable in order to manage NvM jobs. # Data Flow # Linked Runnable - OsTask_Bsw_ReadWrite_AllProcess #Traceability DOM_eCS_TF_P_295, DOM_eCS_TF_P_273
      ptrrAsrOsServicesBswMIf: required-interface=itrAsrOsServices  # # Architecture Element ID ARCH_SW_BswMIf_ptrrOsServicesBswMIf_StartScheduleTableRel_BswM_On_Prep_Shutdown # Description - The StartScheduleTableRel runnable shall be called in the BswM_On_Prep_Shutdown runnable in order to start the default schedule table after main schedule table (RTE) was stopped. # Data Flow # Linked Runnable - BswM_On_Prep_Shutdown #Traceability --------------------------------------------------------------------------------------------------------------------------------- # Architecture Element ID ARCH_SW_BswMIf_ptrrOsServicesBswMIf_StartScheduleTableRel_BswM_OnPostRunFromRun # Description - The StartScheduleTableRel runnable shall be called in the BswM_OnPostRunFromRun runnable in order to start the main schedule table after WriteAll procedure is finished. # Data Flow # Linked Runnable - BswM_OnPostRunFromRun #Traceability --------------------------------------------------------------------------------------------------------------------------------- # Architecture Element ID ARCH_SW_BswMIf_ptrrOsServicesBswMIf_StopScheduleTable_BswM_OnPostRunFromRun # Description - The StopScheduleTable runnable shall be called in the BswM_OnPostRunFromRun runnable in order to stop the default schedule table used to call the ReadWriteAll Os task. # Data Flow # Linked Runnable - BswM_OnPostRunFromRun #Traceability --------------------------------------------------------------------------------------------------------------------------------- # Architecture Element ID ARCH_SW_BswMIf_ptrrOsServicesBswMIf_StopScheduleTable_BswM_CB_NfyNvMJobEnd # Description - The StopScheduleTable runnable shall be called in the BswM_CB_NfyNvMJobEnd runnable in order to stop the default schedule table used to call the ReadWriteAll Os task. # Data Flow # Linked Runnable - BswM_CB_NfyNvMJobEnd #Traceability --------------------------------------------------------------------------------------------------------------------------------- # Architecture Element ID ARCH_SW_BswMIf_ptrrOsServicesBswMIf_StartScheduleTableRel_BswM_CB_NfyNvMJobEnd # Description - The StartScheduleTableRel runnable shall be called in the BswM_CB_NfyNvMJobEnd runnable in order to start the main schedule table after WriteAll procedure is finished. # Data Flow # Linked Runnable - BswM_CB_NfyNvMJobEnd #Traceability --------------------------------------------------------------------------------------------------------------------------------- # Architecture Element ID ARCH_SW_BswMIf_ptrrOsServicesBswMIf_ActivateTask_BswM_OnPostRunFromRun # Description - The ActivateTask runnable shall be called in the BswM_OnPostRunFromRun runnable in order to activate the task dedicated to the ReadAll process fastening. # Data Flow # Linked Runnable - BswM_OnPostRunFromRun #Traceability --------------------------------------------------------------------------------------------------------------------------------- # Architecture Element ID ARCH_SW_BswMIf_ptrrOsServicesBswMIf_ActivateTask_BswM_OnStartupTwoA # Description - The ActivateTask runnable shall be called in the BswM_OnStartupTwoA runnable in order to activate the task dedicated to the ReadAll process fastening. # Data Flow # Linked Runnable - BswM_OnStartupTwoA #Traceability DOM_eCS_TF_P_295 --------------------------------------------------------------------------------------------------------------------------------- # Architecture Element ID ARCH_SW_BswMIf_ptrrOsServicesBswMIf_SetEvent_BswM_OnStartupTwoA # Description - The SetEvent runnable shall be called in the BswM_OnStartupTwoA runnable in order to set the task dedicated to the ReadAll process fastening. # Data Flow # Linked Runnable - BswM_OnStartupTwoA #Traceability DOM_eCS_TF_P_295 --------------------------------------------------------------------------------------------------------------------------------- # Architecture Element ID ARCH_SW_BswMIf_ptrrOsServicesBswMIf_StopScheduleTable_BswM_OnStartComEffective # Description - The StopScheduleTable runnable shall be called in the BswM_OnStartComEffective runnable in order to stop the default schedule table to be able to start the main schedule table. # Data Flow # Linked Runnable - BswM_OnStartComEffective #Traceability --------------------------------------------------------------------------------------------------------------------------------- # Architecture Element ID ARCH_SW_BswMIf_ptrrOsServicesBswMIf_SetEvent_BswM_OnPostRunFromRun # Description - The SetEvent runnable shall be called in the BswM_OnPostRunFromRun runnable in order to set the task dedicated to the WriteAll process fastening. # Data Flow # Linked Runnable - BswM_OnPostRunFromRun #Traceability DOM_eCS_TF_P_264 --------------------------------------------------------------------------------------------------------------------------------- # Architecture Element ID ARCH_SW_BswMIf_ptrrOsServicesBswMIf_ActivateTask_BswM_On_Prep_Shutdown # Description - The ActivateTask runnable shall be called in the BswM_On_Prep_Shutdown runnable in order to activate the task dedicated to the WriteAll process fastening. # Data Flow # Linked Runnable - BswM_On_Prep_Shutdown #Traceability DOM_eCS_TF_P_273 --------------------------------------------------------------------------------------------------------------------------------- # Architecture Element ID ARCH_SW_BswMIf_ptrrOsServicesBswMIf_SetEvent_BswM_On_Prep_Shutdown # Description - The SetEvent runnable shall be called in the BswM_On_Prep_Shutdown runnable in order to set the task dedicated to the WriteAll process fastening. # Data Flow # Linked Runnable - BswM_On_Prep_Shutdown #Traceability DOM_eCS_TF_P_273 --------------------------------------------------------------------------------------------------------------------------------- # Architecture Element ID ARCH_SW_BswMIf_ptrrOsServicesBswMIf_StopScheduleTable_BswM_ProceedReset # Description - The StopScheduleTable runnable shall be called in the BswM_ProceedReset runnable in order to stop the main schedule table. # Data Flow # Linked Runnable - BswM_ProceedReset #Traceability DOM_eCS_TF_P_218 --------------------------------------------------------------------------------------------------------------------------------- # Architecture Element ID ARCH_SW_BswMIf_ptrrOsServicesBswMIf_StartScheduleTable_BswM_ProceedReset # Description - The StartScheduleTable runnable shall be called in the BswM_ProceedReset runnable in order to start the default schedule table. # Data Flow # Linked Runnable - BswM_ProceedReset #Traceability DOM_eCS_TF_P_218 --------------------------------------------------------------------------------------------------------------------------------- # Architecture Element ID ARCH_SW_BswMIf_ptrrOsServicesBswMIf_WaitEvent_OsTask_Bsw_ReadWrite_AllProcess # Description - The WaitEvent runnable shall be called in the OsTask_Bsw_ReadWrite_AllProcess runnable in order to wait for ReadWrite Os task. # Data Flow # Linked Runnable - OsTask_Bsw_ReadWrite_AllProcess #Traceability DOM_eCS_TF_P_295, DOM_eCS_TF_P_273 --------------------------------------------------------------------------------------------------------------------------------- # Architecture Element ID ARCH_SW_BswMIf_ptrrOsServicesBswMIf_ClearEvent_OsTask_Bsw_ReadWrite_AllProcess # Description - The ClearEvent runnable shall be called in the OsTask_Bsw_ReadWrite_AllProcess runnable in order to clear ReadWrite Os task assigned event. # Data Flow # Linked Runnable - OsTask_Bsw_ReadWrite_AllProcess #Traceability DOM_eCS_TF_P_295, DOM_eCS_TF_P_273 --------------------------------------------------------------------------------------------------------------------------------- # Architecture Element ID ARCH_SW_BswMIf_ptrrOsServicesBswMIf_SuspendAllInterrupts_OsTask_Bsw_ReadWrite_AllProcess # Description - The SuspendAllInterrupts runnable shall be called in the OsTask_Bsw_ReadWrite_AllProcess runnable in order to suspend all interrupts. # Data Flow # Linked Runnable - OsTask_Bsw_ReadWrite_AllProcess #Traceability DOM_eCS_TF_P_295, DOM_eCS_TF_P_273 --------------------------------------------------------------------------------------------------------------------------------- # Architecture Element ID ARCH_SW_BswMIf_ptrrOsServicesBswMIf_ResumeAllInterrupts_OsTask_Bsw_ReadWrite_AllProcess # Description - The ResumeAllInterrupts runnable shall be called in the OsTask_Bsw_ReadWrite_AllProcess runnable in order to resume all interrupts. # Data Flow # Linked Runnable - OsTask_Bsw_ReadWrite_AllProcess #Traceability DOM_eCS_TF_P_295, DOM_eCS_TF_P_273 --------------------------------------------------------------------------------------------------------------------------------- # Architecture Element ID ARCH_SW_BswMIf_ptrrOsServicesBswMIf_TerminateTask_OsTask_Bsw_ReadWrite_AllProcess # Description - The TerminateTask runnable shall be called in the OsTask_Bsw_ReadWrite_AllProcess runnable in order to terminate task when all blocks have been correctly managed. # Data Flow # Linked Runnable - OsTask_Bsw_ReadWrite_AllProcess #Traceability DOM_eCS_TF_P_295, DOM_eCS_TF_P_273 --------------------------------------------------------------------------------------------------------------------------------- # Architecture Element ID ARCH_SW_BswMIf_ptrrOsServicesBswMIf_SetEvent_OsTask_Bsw_ReadWrite_AllProcess # Description - The SetEvent runnable shall be called in the OsTask_Bsw_ReadWrite_AllProcess runnable in order to set the event in OS task. # Data Flow # Linked Runnable - OsTask_Bsw_ReadWrite_AllProcess #Traceability DOM_eCS_TF_P_295, DOM_eCS_TF_P_273
      ptrrAsrPduRServicesBswMIf: required-interface=itrAsrPduRServices  # # Architecture Element ID ARCH_SW_BswMIf_ptrrPduRServicesBswMIf_PduR_Init_BswM_OnStartupTwoA # Description - The PduR_Init runnable shall be called in the BswM_OnStartupTwoA runnable in order to initialize the PduR module. # Data Flow # Linked Runnable - BswM_OnStartupTwoA #Traceability
      ptrrAsrRteServicesBswMIf: required-interface=itrAsrRteServices  # # Architecture Element ID ARCH_SW_BswMIf_ptrrRteServicesBswMIf_Rte_Start_BswM_OnStartComEffective # Description - The Rte_Start runnable shall be called in the BswM_OnStartComEffective runnable in order to start RTE services # Data Flow # Linked Runnable - BswM_OnStartComEffective #Traceability # Architecture Element ID ARCH_SW_BswMIf_ptrrRteServicesBswMIf_Rte_Stop_BswM_On_Prep_Shutdown # Description - The Rte_Stop runnable shall be called in the BswM_On_Prep_Shutdown runnable in order to stop RTE services # Data Flow # Linked Runnable - BswM_On_Prep_Shutdown #Traceability
      ptrrAtmServicesBswMIf: required-interface=itrAtmServices  # # Architecture Element ID ARCH_SW_BswMIf_ptrrAtmServicesBswMIf_ATM_Init_BswM_OnStartComEffective # Description - The ATM_Init runnable shall be called in the BswM_OnStartComEffective runnable in order to initialize ATM module # Data Flow # Linked Runnable - BswM_OnStartComEffective #Traceability
      ptrrCilServicesBswMIf: required-interface=itrCilServices  # # Architecture Element ID ARCH_SW_BswMIf_ptrrCilServicesBswMIf_CIL_runInit_BswM_OnStartComEffective # Description - The CIL_runInit runnable shall be called in the BswM_OnStartComEffective runnable in order to initialize CIL module # Data Flow # Linked Runnable - BswM_OnStartComEffective #Traceability
      ptrrDiaServicesBswMIf: required-interface=itrDiaServices  # # Architecture Element ID ARCH_SW_BswMIf_ptrrDiaServicesBswMIf_DIA_Init_BswM_OnStartComEffective # Description - The DIA_Init runnable shall be called in the BswM_OnStartComEffective runnable in order to initialize DIA module to be able to manage diagnostic requests. # Data Flow # Linked Runnable - BswM_OnStartComEffective #Traceability DOM_eCS_TF_P_165
      ptrrFsmServicesBswMIf: required-interface=itrFsmServices  # # Architecture Element ID ARCH_SW_BswMIf_ptrrFsmServicesBswMIf_FSM_Init_BswM_OnStartupTwoB # Description - The FSM_Init runnable shall be called in the BswM_OnStartupTwoB runnable in order to initialize FSM module # Data Flow # Linked Runnable - BswM_OnStartupTwoB #Traceability --------------------------------------------------------------------------------------------------------------------------------------------- # Architecture Element ID ARCH_SW_BswMIf_ptrrFsmServicesBswMIf_FSM_ModesInit_BswM_OnStartComEffective # Description - The FSM_ModesInit runnable shall be called in the BswM_OnStartComEffective runnable in order to initialize FSM context modes module # Data Flow # Linked Runnable - BswM_OnStartComEffective #Traceability
      ptrrLpmServicesBswMIf: required-interface=itrLpmServices  # # Architecture Element ID ARCH_SW_BswMIf_ptrrLpmServicesBswMIf_LPM_sleepInit_BswM_OnLowPwrFromPostRun # Description - The LPM_sleepInit runnable shall be called in the BswM_OnLowPwrFromPostRun runnable in order to initialize LPM module # Data Flow # Linked Runnable - BswM_OnLowPwrFromPostRun #Traceability DOM_eCS_TF_P_200, DOM_eCS_TF_P_265, DOM_eCS_TF_P_205, DOM_eCS_TF_P_268 --------------------------------------------------------------------------------------------------------------------------------------------- # Architecture Element ID ARCH_SW_BswMIf_ptrrLpmServicesBswMIf_LPM_sleepMainLoop_BswM_OnLowPwrFromPostRun # Description - The LPM_sleepMainLoop runnable shall be called in the BswM_OnLowPwrFromPostRun runnable in order to enter in main loop and stay there until: - Passenger occupancy detected - Bus activity detected - TLowPower timeout # Data Flow # Linked Runnable - BswM_OnLowPwrFromPostRun #Traceability DOM_eCS_TF_P_200, DOM_eCS_TF_P_269, DOM_eCS_TF_P_208, DOM_eCS_TF_P_271, DOM_eCS_TF_P_214, DOM_eCS_TF_P_317, DOM_eCS_TF_P_235, DOM_eCS_TF_P_352 --------------------------------------------------------------------------------------------------------------------------------------------- # Architecture Element ID ARCH_SW_BswMIf_ptrrLpmServicesBswMIf_LPM_sleepRestore_BswM_OnLowPwrFromPostRun # Description - The LPM_sleepRestore runnable shall be called in the BswM_OnLowPwrFromPostRun runnable in order to restore previous state and set rules to go back in RUN STATE # Data Flow # Linked Runnable - BswM_OnLowPwrFromPostRun #Traceability DOM_eCS_TF_P_200, DOM_eCS_TF_P_214, DOM_eCS_TF_P_317, DOM_eCS_TF_P_216
      ptrrMcuIfServicesBswMIf: required-interface=itrMcuIfServices  # # Architecture Element ID ARCH_SW_BswMIf_ptrrMcuIfServicesBswMIf_McuIf_runInit # Description - The McuIf_runInit shall be called in the BswM_OnRunFromWakeup runnable in order to initialize and calculate initial values of PORT, ADC and FTM CRC's. # Data Flow # Linked Runnable - McuIf_runInit #Traceability
      ptrrMicServices: required-interface=itrMicServices  # # Architecture Element ID ARCH_SW_BswMIf_ptrrMicServicesBswMIf_MIC_Init_BswM_OnStartupTwoA # Description - The MIC_Init runnable shall be called in the BswM_OnStartupTwoA runnable in order to initialize MIC module # Data Flow # Linked Runnable - BswM_OnStartupTwoA #Traceability
      ptrrRcmServicesBswMIf: required-interface=itrRcmServices  # # Architecture Element ID ARCH_SW_BswMIf_ptrrRcmServicesBswMIf_RCM_DetermineResetCause_BswM_OnStartComEffective # Description - The RCM_DetermineResetCause runnable shall be called in the BswM_OnStartComEffective runnable in order to determine the reset reason. # Data Flow # Linked Runnable - BswM_OnStartComEffective #Traceability DOM_eCS_TF_P_249
      ptrrSadServicesBswMIf: required-interface=itrSadServices  # # Architecture Element ID ARCH_SW_BswMIf_ptrrSadServicesBswMIf_SAD_Init_BswM_OnStartComEffective # Description - The SAD_Init runnable shall be called in the BswM_OnStartComEffective runnable in order to initialize SAD module # Data Flow # Linked Runnable - BswM_OnStartComEffective #Traceability
